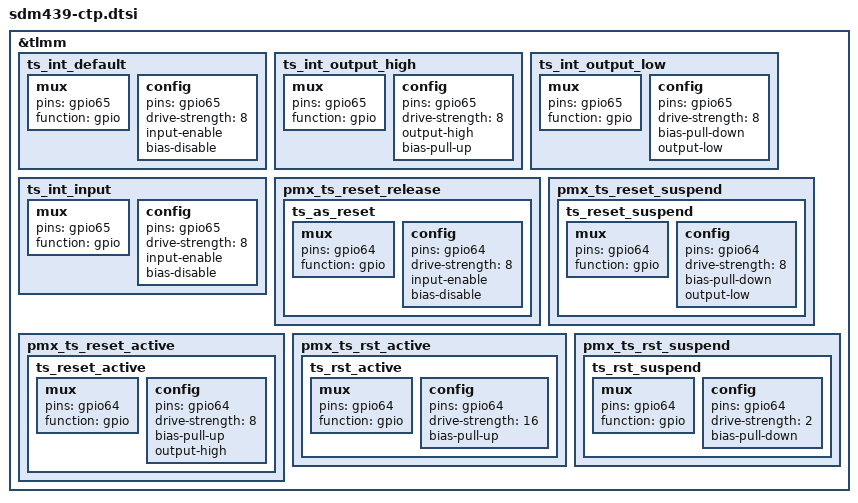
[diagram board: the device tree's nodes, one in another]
/* Copyright (c) 2018, The Linux Foundation. All rights reserved.
 * Copyright (C) 2021 XiaoMi, Inc.
 *
 * it under the terms of the GNU General Public License version 2 and
 * only version 2 as published by the Free Software Foundation.
 *
 * This program is distributed in the hope that it will be useful,
 * but WITHOUT ANY WARRANTY; without even the implied warranty of
 * MERCHANTABILITY or FITNESS FOR A PARTICULAR PURPOSE.  See the
 * GNU General Public License for more details.
 */

/*
 * As a general rule, only version-specific property overrides should be placed
 * inside this file. However, device definitions should be placed inside the
 * yep_product_ql1001_flatform.dtsi file.
 */

&tlmm {
		ts_int_default: ts_int_default {
			mux {
				pins = "gpio65";
				function = "gpio";
			};
			config {
				pins = "gpio65";
				drive-strength = <8>;
				/*bias-pull-up;*/
				input-enable;
				bias-disable;
			};
		};

		ts_int_output_high: ts_int_output_high {
			mux {
				pins = "gpio65";
				function = "gpio";
			};
			config {
				pins = "gpio65";
				drive-strength = <8>;
				output-high;
				bias-pull-up;
			};
		};

		ts_int_output_low: ts_int_output_low {
			mux {
				pins = "gpio65";
				function = "gpio";
			};
			config {
				pins = "gpio65";
				drive-strength = <8>;
				bias-pull-down;
				output-low;
			};
		};

		ts_int_input: ts_int_input {
			mux {
				pins = "gpio65";
				function = "gpio";
			};
			config {
				pins = "gpio65";
				drive-strength = <8>;
				input-enable;
				bias-disable;
			};
		};

		pmx_ts_reset_release {
			ts_as_reset: ts_as_reset {
				mux {
					pins = "gpio64";
					function = "gpio";
				};

				config {
					pins = "gpio64";
					drive-strength = <8>;
					input-enable;
					bias-disable;
				};
			};
		};

		pmx_ts_reset_suspend {
			ts_reset_suspend: ts_reset_suspend {
				mux {
					pins = "gpio64";
					function = "gpio";
				};

				config {
					pins = "gpio64";
					drive-strength = <8>;
					bias-pull-down;
					output-low;
				};
			};
		};

		pmx_ts_reset_active {
			ts_reset_active: ts_reset_active {
				mux {
					pins = "gpio64";
					function = "gpio";
				};

				config {
					pins = "gpio64";
					drive-strength = <8>;
					bias-pull-up;
					output-high;
				};
			};
		};

		pmx_ts_rst_active {
				ts_rst_active: ts_rst_active {
						mux {
								pins = "gpio64";
								function = "gpio";
						};

						config {
								pins = "gpio64";
								drive-strength = <16>;
								bias-pull-up;
						};
				};
		};

		pmx_ts_rst_suspend {
			ts_rst_suspend: ts_rst_suspend {
						mux {
								pins = "gpio64";
								function = "gpio";
						};

						config {
								pins = "gpio64";
								drive-strength = <2>;
								bias-pull-down;
						};
				};
		};
};
